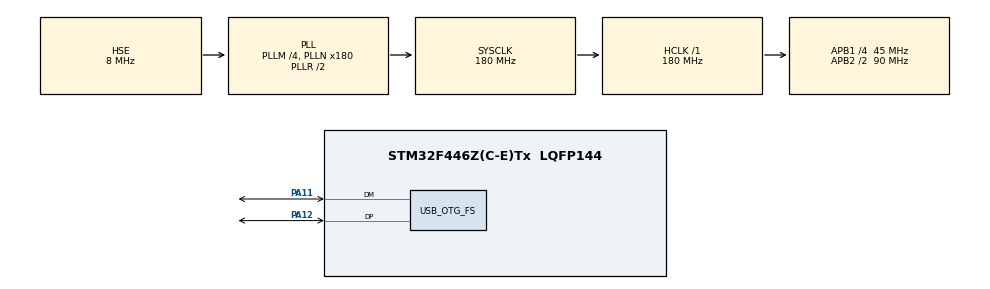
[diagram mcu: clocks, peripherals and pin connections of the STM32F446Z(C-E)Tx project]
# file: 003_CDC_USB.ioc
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Mcu.Family=STM32F4
Mcu.Name=STM32F446Z(C-E)Tx
Mcu.Package=LQFP144
NVIC.OTG_FS_IRQn=true\:0\:0\:false\:false\:true\:false\:true\:true
NVIC.PriorityGroup=NVIC_PRIORITYGROUP_4
PA11.Mode=Device_Only
PA11.Signal=USB_OTG_FS_DM
PA12.Mode=Device_Only
PA12.Signal=USB_OTG_FS_DP
PA13.Mode=Serial_Wire
PA13.Signal=SYS_JTMS-SWDIO
PA14.Mode=Serial_Wire
PA14.Signal=SYS_JTCK-SWCLK
PC14-OSC32_IN.Mode=LSE-External-Oscillator
PC14-OSC32_IN.Signal=RCC_OSC32_IN
PC15-OSC32_OUT.Mode=LSE-External-Oscillator
PC15-OSC32_OUT.Signal=RCC_OSC32_OUT
PH0-OSC_IN.Mode=HSE-External-Oscillator
PH0-OSC_IN.Signal=RCC_OSC_IN
PH1-OSC_OUT.Mode=HSE-External-Oscillator
PH1-OSC_OUT.Signal=RCC_OSC_OUT
ProjectManager.HeapSize=0x200
ProjectManager.StackSize=0x400
ProjectManager.TargetToolchain=STM32CubeIDE
RCC.48MHZClocksFreq_Value=24000000
RCC.AHBFreq_Value=180000000
RCC.APB1CLKDivider=RCC_HCLK_DIV4
RCC.APB1Freq_Value=45000000
RCC.APB1TimFreq_Value=90000000
RCC.APB2CLKDivider=RCC_HCLK_DIV2
RCC.APB2Freq_Value=90000000
RCC.APB2TimFreq_Value=180000000
RCC.CortexFreq_Value=180000000
RCC.HCLKFreq_Value=180000000
RCC.HSE_VALUE=8000000
RCC.HSI_VALUE=16000000
RCC.PLLM=4
RCC.PLLMUL=RCC_PLL_MUL9
RCC.PLLN=180
RCC.PLLQ=7
RCC.PLLSAIM=4
RCC.PLLSAIN=96
RCC.PLLSAIP=RCC_PLLSAIP_DIV4
RCC.PLLSourceVirtual=RCC_PLLSOURCE_HSE
RCC.PRESCALERUSB=RCC_USBCLKSOURCE_PLL_DIV1_5
RCC.SYSCLKFreq_VALUE=180000000
RCC.SYSCLKSource=RCC_SYSCLKSOURCE_PLLRCLK
RCC.SYSCLKSourceVirtual=RCC_SYSCLKSOURCE_PLLCLK
RCC.USBCLockSelection=RCC_CLK48CLKSOURCE_PLLSAIP
RCC.USBFreq_Value=48000000
RCC.VCOOutputFreq_Value=360000000
USB_DEVICE.CLASS_NAME_FS=CDC
USB_DEVICE.VirtualMode-CDC_FS=Cdc
USB_DEVICE.VirtualModeFS=Cdc_FS
USB_OTG_FS.VirtualMode=Device_Only
VP_USB_DEVICE_VS_USB_DEVICE_CDC_FS.Mode=CDC_FS
board=NUCLEO-F446ZE

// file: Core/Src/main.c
/* USER CODE BEGIN Header */
/**
  ******************************************************************************
  * @file           : main.c
  * @brief          : Main program body
  ******************************************************************************
  * @attention
  *
  * Copyright (c) 2026 STMicroelectronics.
  * All rights reserved.
  *
  * This software is licensed under terms that can be found in the LICENSE file
  * in the root directory of this software component.
  * If no LICENSE file comes with this software, it is provided AS-IS.
  *
  ******************************************************************************
  */
/* USER CODE END Header */
#include "main.h"
#include "usb_device.h"

void SystemClock_Config(void);
static void MX_GPIO_Init(void);

/* USER CODE BEGIN 0 */
int8_t buff[20]="helllo bhai\r\n";
/* USER CODE END 0 */

int main(void)
{

  /* MCU Configuration--------------------------------------------------------*/

  /* Reset of all peripherals, Initializes the Flash interface and the Systick. */
  HAL_Init();

  /* Configure the system clock */
  SystemClock_Config();

  /* Initialize all configured peripherals */
  MX_GPIO_Init();
  MX_USB_DEVICE_Init();

  /* Infinite loop */
  while (1)
  {

    /* USER CODE BEGIN 3 */
	  CDC_Transmit_FS(buff,sizeof(buff));
	  HAL_Delay(100);
  }
  /* USER CODE END 3 */
}

void SystemClock_Config(void)
{
  RCC_OscInitTypeDef RCC_OscInitStruct = {0};
  RCC_ClkInitTypeDef RCC_ClkInitStruct = {0};

  /** Configure the main internal regulator output voltage
  */
  __HAL_RCC_PWR_CLK_ENABLE();
  __HAL_PWR_VOLTAGESCALING_CONFIG(PWR_REGULATOR_VOLTAGE_SCALE1);

  /** Initializes the RCC Oscillators according to the specified parameters
  * in the RCC_OscInitTypeDef structure.
  */
  RCC_OscInitStruct.OscillatorType = RCC_OSCILLATORTYPE_HSE;
  RCC_OscInitStruct.HSEState = RCC_HSE_ON;
  RCC_OscInitStruct.PLL.PLLState = RCC_PLL_ON;
  RCC_OscInitStruct.PLL.PLLSource = RCC_PLLSOURCE_HSE;
  RCC_OscInitStruct.PLL.PLLM = 4;
  RCC_OscInitStruct.PLL.PLLN = 180;
  RCC_OscInitStruct.PLL.PLLP = RCC_PLLP_DIV2;
  RCC_OscInitStruct.PLL.PLLQ = 7;
  RCC_OscInitStruct.PLL.PLLR = 2;
  if (HAL_RCC_OscConfig(&RCC_OscInitStruct) != HAL_OK)
  {
    Error_Handler();
  }

  /** Activate the Over-Drive mode
  */
  if (HAL_PWREx_EnableOverDrive() != HAL_OK)
  {
    Error_Handler();
  }

  /** Initializes the CPU, AHB and APB buses clocks
  */
  RCC_ClkInitStruct.ClockType = RCC_CLOCKTYPE_HCLK|RCC_CLOCKTYPE_SYSCLK
                              |RCC_CLOCKTYPE_PCLK1|RCC_CLOCKTYPE_PCLK2;
  RCC_ClkInitStruct.SYSCLKSource = RCC_SYSCLKSOURCE_PLLRCLK;
  RCC_ClkInitStruct.AHBCLKDivider = RCC_SYSCLK_DIV1;
  RCC_ClkInitStruct.APB1CLKDivider = RCC_HCLK_DIV4;
  RCC_ClkInitStruct.APB2CLKDivider = RCC_HCLK_DIV2;

  if (HAL_RCC_ClockConfig(&RCC_ClkInitStruct, FLASH_LATENCY_5) != HAL_OK)
  {
    Error_Handler();
  }
}

static void MX_GPIO_Init(void)
{

  /* GPIO Ports Clock Enable */
  __HAL_RCC_GPIOC_CLK_ENABLE();
  __HAL_RCC_GPIOH_CLK_ENABLE();
  __HAL_RCC_GPIOA_CLK_ENABLE();

}

void Error_Handler(void)
{
  __disable_irq();
  while (1)
  {
  }
}
